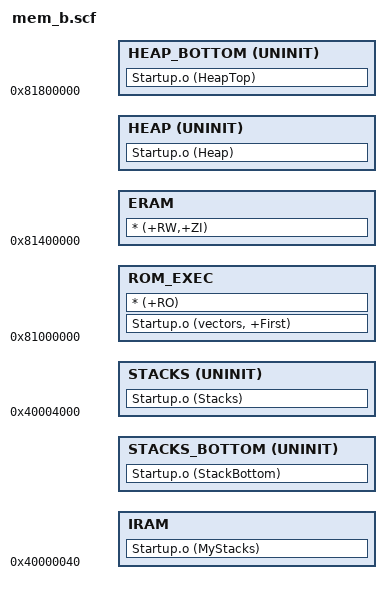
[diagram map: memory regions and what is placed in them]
;/****************************************Copyright (c)**************************************************
;**                               Guangzou ZLG-MCU Development Co.,LTD.
;**                                      graduate school
;**                                 http://www.zlgmcu.com
;**
;**--------------File Info-------------------------------------------------------------------------------
;** File Name: men_b.scf
;** Last modified Date:  2004-09-17
;** Last Version: 1.0
;** Descriptions: Scatter File
;**
;**------------------------------------------------------------------------------------------------------
;** Created By: Chenmingji
;** Created date:   2004-09-17
;** Version: 1.0
;** Descriptions: First version
;**
;**------------------------------------------------------------------------------------------------------
;** Modified by:            Ganda
;** Modified date:          2005-06-15
;** Version:                1.01
;** Descriptions:           Only for MagicARM2200
;**
;**------------------------------------------------------------------------------------------------------
;** Modified by: 
;** Modified date:
;** Version: 
;** Descriptions:  
;**
;********************************************************************************************************/

ROM_LOAD 0x81000000                 ;// Origination Point of Code (Code in Exram)
{
    ROM_EXEC 0x81000000             ;// Origination Point of Executing
    {
        Startup.o (vectors, +First)
        * (+RO)
    }


    IRAM 0x40000040                 ;// Origination Point of Internal SRAM
    {                               ;// 0x40000000 ~ 0x4000003F for Vector
        Startup.o (MyStacks)
    }

    STACKS_BOTTOM +0 UNINIT
    {
        Startup.o (StackBottom)
    }

    STACKS 0x40004000 UNINIT        ;// End Point of Internal SRAM
    {
        Startup.o (Stacks)
    }

    ERAM 0x81400000                 ;// Origination Point of External SRAM
    {                               ;// 0x81000000 ~ 0x813FFFFF for Code
        * (+RW,+ZI)
    }

    HEAP +0 UNINIT
    {
        Startup.o (Heap)
    }

    HEAP_BOTTOM 0x81800000 UNINIT   ;// End Point of External SRAM
    {
        Startup.o (HeapTop)
    }

}

